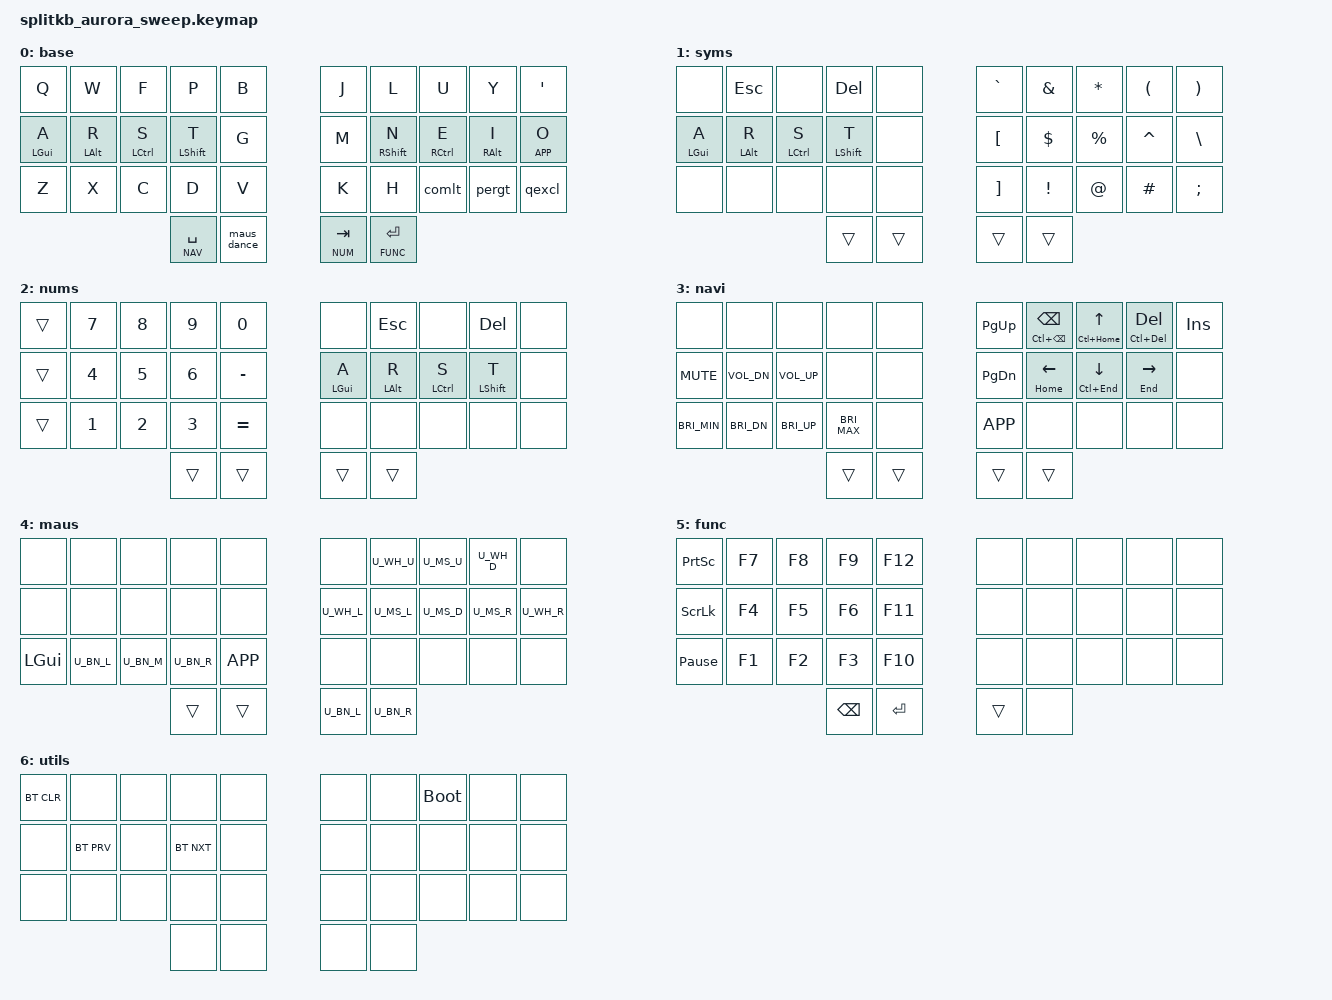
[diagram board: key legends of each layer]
#include <behaviors.dtsi>
#include <dt-bindings/zmk/keys.h>
#include <dt-bindings/zmk/bt.h>

// Initially derived from https://github.com/guruc13/zmk_sweep_colemak_dh
// Which is derived from https://github.com/manna-harbour/miryoku
// Now lots of stuff directly from urob's zmk work

#include "../zmk-nodefree-config/helper.h"
#include "../zmk-nodefree-config/keypos_def/keypos_34keys.h"

#define BASE 0
#define SYM  1    // Hold ---
#define NUM  2    // Hold RH0
#define NAV  3    // Hold LH1
#define MAUS 4    // Hold LH0
#define FUNC 5    // Hold RH1
#define UTIL 6    // Hold RH0 + RH1

// must be sourced after layer-shortcuts and after keypos_34keys.h
#include "combos.dtsi"  // references layer defs we are not using
#include "mouse.dtsi"

&mt {
    flavor = "tap-preferred";
    tapping-term-ms = <220>;
    quick-tap-ms = <220>;              // repeat on tap-into-hold
    hold-trigger-key-positions = <0>;  // tap on interrupt
};

#define NAV_L     &mt HOME     LEFT    // tap: left  | long-tap: beginning of line
#define NAV_R     &mt END      RIGHT   // tap: right | long-tap: end       of line
#define NAV_U     &mt LC(HOME) UP      // tap: up    | long-tap: beginning of document
#define NAV_D     &mt LC(END)  DOWN    // tap: down  | long-tap: end       of document
#define NAV_BSC  &mt LC(BSPC) BSPC    // tap: bspc  | long-tap: delete word backward
#define NAV_DEL   &mt LC(DEL)  DEL     // tap: del   | long-tap: delete word forward


#define KEYS_L LT0 LT1 LT2 LT3 LT4 LM0 LM1 LM2 LM3 LM4 LB0 LB1 LB2 LB3 LB4  // left-hand keys
#define KEYS_R RT0 RT1 RT2 RT3 RT4 RM0 RM1 RM2 RM3 RM4 RB0 RB1 RB2 RB3 RB4  // right-hand keys
#define THUMBS LH1 LH0 RH0 RH1                                      // thumb keys

#define QUICK_TAP_MS 175

ZMK_BEHAVIOR(hml, hold_tap,  // left-hand HRMs
    flavor = "balanced";
    tapping-term-ms = <280>;
    quick-tap-ms = <QUICK_TAP_MS>;
    global-quick-tap-ms = <150>;        // requires PR #1387
    bindings = <&kp>, <&kp>;
    hold-trigger-key-positions = <KEYS_R THUMBS>;
    hold-trigger-on-release;            // requires PR #1423
)


ZMK_BEHAVIOR(hmr, hold_tap,  // right-hand HRMs
    flavor = "balanced";
    tapping-term-ms = <280>;
    quick-tap-ms = <QUICK_TAP_MS>;
    global-quick-tap-ms = <150>;        // requires PR #1387
    bindings = <&kp>, <&kp>;
    hold-trigger-key-positions = <KEYS_L THUMBS>;
    hold-trigger-on-release;            // requires PR #1423
)

// mouse layer that deactivates automatically on all other keys, requires PR #1366
ZMK_BEHAVIOR(smart_maus, tri_state,
    bindings = <&tog MAUS>, <&none>, <&tog MAUS>;
    ignored-key-positions = <RT1 RT2 RT3 RM1 RM2 RM3 RM4 RH0 RH1>;  // mouse keys
    ignored-layers = <MAUS>;
)


// tap:  backspace | double-tap: sticky maus-layer | hold: maus-layer
ZMK_BEHAVIOR(maus_dance, tap_dance,
    tapping-term-ms = <200>;
    bindings = <&kp BSPC>, <&smart_maus>;
)

// tap: qmark | shift + tap: excl
ZMK_BEHAVIOR(qexcl, mod_morph,
    bindings = <&kp QMARK>, <&kp EXCL>;
    mods = <(MOD_LSFT|MOD_RSFT)>;
)

// tap: comma | shift + tap: semi-colon
ZMK_BEHAVIOR(csemi, mod_morph,
    bindings = <&kp COMMA>, <&kp SEMI>;
    mods = <(MOD_LSFT|MOD_RSFT)>;
)

// tap: period | shift + tap: COLON
ZMK_BEHAVIOR(pcolon, mod_morph,
    bindings = <&kp PERIOD>, <&kp COLON>;
    mods = <(MOD_LSFT|MOD_RSFT)>;
)

// tap: period | shift + tap: semi | alt + shift + tap: <
ZMK_BEHAVIOR(comlt, mod_morph,
    bindings = <&kp COMMA>, <&kp LESS_THAN>;
    mods = <(MOD_LALT|MOD_RALT)>;
)

// tap: period | shift + tap: colon | gui + shift + tap: >
ZMK_BEHAVIOR(pergt, mod_morph,
    bindings = <&kp PERIOD>, <&kp GREATER_THAN>;
    mods = <(MOD_LALT|MOD_RALT)>;
)


/ {

  conditional_layers {
    compatible = "zmk,conditional-layers";
    cond_layer_util {
        if-layers = <NUM FUNC>;
        then-layer = <UTIL>;
    };
  };


  keymap {
    compatible = "zmk,keymap";

// 0 BASE LAYER SYM combos
//     4       3       2      1       0             0       1       2      3      4
// ╭───────┬───────┬──────┬───────┬───────╮     ╭───────┬───────┬───────┬──────┬──────╮
// │       │     ESC     TAB      │       │     │       │     LBRC     RBRC    │      │
// │       │       │      │       │       │  T  │       │       │       │      │      │
// ├───────┼──AT───┼─HASH─┼─DLLR──┼─PRCNT─┤     ├─CARET ┼─PLUS──┼─ASTRK─┼─AMPS─┼──────┤
// │       │       │      │       │       │     │       │       │       │      │      │
// │       │    REPEAT   ENTER    │       │  M  │       │     LPAR     RPAR    │      │
// │       │       │      │       │       │     │       │       │       │      │      │
// ├───────┼─GRAVE─┼─BSLH─┼─EQUAL─│ TILDE─┤     ├─UNDER─┼─MINUS─┼─SLASH─┼─PIPE─┼──────┤
// │       │       │      │       │       │     │       │       │       │      │      │
// │       │    COPY    PASTE     │       │  B  │       │     LBKT     RBKT    │      │
// ╰───────┴───────┴──────╮───────┴───────┤     ├───────┴───────╭───────┴──────┴──────╯
//                        │       ┬       │  H  │       ┬       │
//           LEFT         │       │       │     │       │       │    RIGHT
//                        ╰───────┴───────╯     ╰───────┴───────╯
//

// 0 BASE LAYER
// ╭───────┬──────┬───────┬──────┬──────╮     ╭──────┬──────┬───────┬────────┬───────╮
// │       │      │       │      │      │     │      │      │       │        │  DQT  │
// │   Q   │   W  │   F   │   P  │   B  │     │  J   │   L  │   U   │    Y   │  SQT  │
// ├───────┼──────┼───────┼──────┼──────┤     ├──────┼──────┼───────┼────────┼───────┤
// │ LGUI  │ LALT │ LCT L │ LSHT │      │     │      │ LSHT │ LCTL  │  LALT  │ K_APP │
// │   A   │   R  │   S   │   T  │   G  │     │  M   │   N  │   E   │    I   │   O   │
// ├───────┼──────┼───────┼──────┼──────┤     ├──────┼──────┼───────┼────────┼───────┤
// │       │      │       │      │      │     │      │      │   LT  │   GT   │ EXCL  │
// │   Z   │   X  │   C   │   D  │   V  │     │  K   │   H  │ COMMA │ PERIOD │ QMARK │
// ╰───────┴──────┴──╮────┴──────┴──────┤     ├──────┴──────┴─────╭─┴────────┴───────╯
//                   │                  │     │      UTIL(6)      │
//                   │ NAV(3) ┬ MAUS(4) │     │ NUM(2) ┬  FUNC(5) │
//                   │ SPACE  │  BSPC   │     │   TAB  │  ENTER   │
//                   ╰────────┴─────────╯     ╰────────┴──────────╯
//

    base_layer { // layer 0
      label = "base";
      bindings = <
      &kp Q       &kp W       &kp F        &kp P        &kp B     &kp J  &kp L         &kp U        &kp Y        &kp SQT
      &hml LGUI A &hml LALT R &hml LCTRL S &hml LSHFT T &kp G     &kp M  &hmr RSHFT N  &hmr RCTRL E &hmr RALT I &hmr K_APP O
      &kp Z       &kp X       &kp C        &kp D        &kp V     &kp K  &kp H         &comlt    &pergt  &qexcl
                                 &lt NAV SPACE    &maus_dance     &lt NUM TAB  &lt FUNC ENTER
        >;
    };

// 1 SYMS LAYER
// ╭──────┬──────┬──────┬──────┬──────╮    ╭───────┬───────┬───────┬───────┬───────╮
// │      │      │      │      │      │    │ TILDE │       │       │       │       │
// │      │ ESC  │      │ DEL  │      │    │ GRAVE │ AMPS  │ ASTRK │ LPAR  │ RPAR  │
// ├──────┼──────┼──────┼──────┼──────┤    ├───────┼───────┼───────┼───────┼───────┤
// │      │      │      │      │      │    │ LBRC  │       │       │       │ PIPE  │
// │ LGUI │ LALT │ LCTL │ LSHT │      │    │ LBKT  │ DLLR  │ PRCNT │ CARET │ BSLH  │
// ├──────┼──────┼──────┼──────┼──────┤    ├───────┼───────┼───────┼───────┼───────┤
// │      │      │      │      │      │    │ RBRC  │       │       │       │ COLON │
// │      │      │      │      │      │    │ RBKT  │ EXCL  │  AT   │ HASH  │ SEMI  │
// ╰──────┴──────┴────╮─┴──────┴──────┤    ├───────┼───────╭───────┴───────┴───────╯
//                    │    MAUS(4)    │    │               │
//                    │ **** ┬  (NUM) │    │       ┬       │
//                    │ **** │  TRANS │    │ TRANS │ TRANS │
//                    ╰──────┴────────╯    ╰───────┴───────╯
//

    sym_layer { //layer 1
      label = "syms";
      bindings = <
      &none       &kp ESC     &none        &kp DEL      &none      &kp GRAVE &kp AMPS &kp ASTRK &kp LPAR  &kp RPAR
      &hml LGUI A &hml LALT R &hml LCTRL S &hml LSHFT T &none      &kp LBKT  &kp DLLR &kp PRCNT &kp CARET &kp BSLH
      &none       &none       &none        &none        &none      &kp RBKT  &kp EXCL &kp AT    &kp HASH  &kp SEMI
                                           &trans       &trans     &trans    &trans
      >;
    };


// 2 NUMS LAYER
//  ╭───────┬───────┬───────┬───────┬───────╮    ╭───────┬──────┬──────┬──────┬──────╮
//  │       │ AMPS  │ ASTRK │ LPAR  │ RPAR  │    │       │      │      │      │      │
//  │ TRANS │  N7   │   N8  │  N9   │   N0  │    │       │ ESC  │      │ DEL  │      │
//  ├───────┼───────┼───────┼───────┼───────┤    ├───────┼──────┼──────┼──────┼──────┤
//  │       │ DLLR  │ PRCNT │ CARET │ UNDER │    │       │      │      │      │      │
//  │ TRANS │  N4   │   N5  │   N6  │ MINUS │    │ LGUI  │ LALT │ LCTL │ LSHT │      │
//  ├───────┼───────┼───────┼───────┼───────┤    ├───────┼──────┼──────┼──────┼──────┤
//  │       │ EXCL  │   AT  │  HASH │ PLUS  │    │       │      │      │      │      │
//  │ TRANS │  N1   │   N2  │   N3  │ EQUAL │    │       │      │      │      │      │
//  ╰───────┴───────┴───────┼───────├───────┤    ├───────┼───────╭─────┴──────┴──────╯
//                          │               │    │               │
//                          │       ┬       │    │       ┬       │
//                          │ TRANS │ TRANS │    │ TRANS │ TRANS │
//                          ╰───────┴───────╯    ╰───────┴───────╯
//

    num_layer { //layer 2
      label = "nums";
      bindings = <
      &trans &kp N7  &kp N8  &kp N9  &kp N0        &none       &kp ESC     &none        &kp DEL      &none
      &trans &kp N4  &kp N5  &kp N6  &kp MINUS     &hml LGUI A &hml LALT R &hml LCTRL S &hml LSHFT T &none
      &trans &kp N1  &kp N2  &kp N3  &kp EQUAL     &none       &none       &none        &none        &none
                             &trans  &trans         &trans       &trans
      >;
    };


// 3 NAV LAYER
// ╭──────┬──────┬──────┬───────┬───────╮   ╭────────┬────────┬───────┬───────┬────╮
// │      │      │      │       │       │   │ UNDO   │  CUT   │ COPY  │ PASTE │    │
// │      │ HOME │  UP  │ PG_UP │  INS  │   │ LC(Z)  │ LC(X)  │ LC(C) │ LC(V) │    │
// ├──────┼──────┼──────┼───────┼───────┤   ├────────┼────────┼───────┼───────┼────┤
// │      │      │      │       │       │   │        │ K_VOL  │ K_VOL │       │    │
// │ CAPS │ LEFT │ DOWN │ RIGHT │  DEL  │   │ K_MUTE │  _DN   │  _UP  │       │    │
// ├──────┼──────┼──────┼───────┼───────┤   ├────────┼────────┼───────┼───────┼────┤
// │      │      │      │       │       │   │ C_BRI  │ C_BRI  │ C_BRI │ C_BRI │    │
// │ LGUI │ END  │      │ PG_DN │ K_APP │   │  _MIN  │  _DN   │  _UP  │  _MAX │    │
// ╰──────┴──────┴──────╮───────┼───────┤   ├────────┴────────╭───────┴───────┴────╯
//                      │               │   │                 │
//                      │       ┬       │   │        ┬        │
//                      │ TRANS │ TRANS │   │ TRANS  │ TRANS  │
//                      ╰───────┴───────╯   ╰────────┴────────╯
//

    nav_layer { //layer 3
      label = "navi";
      bindings = <
      &none         &none        &none        &none          &none     &kp PG_UP  NAV_BSC NAV_U  NAV_DEL &kp INS
      &kp K_MUTE    &kp K_VOL_DN &kp K_VOL_UP &none          &none     &kp PG_DN  NAV_L   NAV_D  NAV_R   &none
      &kp C_BRI_MIN &kp C_BRI_DN &kp C_BRI_UP &kp C_BRI_MAX  &none     &kp K_APP  &none   &none  &none   &none
                                              &trans         &trans    &trans     &trans
      >;
    };

// 4 MAUS LAYER
// ╭──────┬──────┬──────┬──────┬───────╮  ╭────────┬────────┬────────┬────────┬─────────╮
// │      │      │      │      │       │  │        │ SCROLL │  MOVE  │ SCROLL │         │
// │      │      │      │      │       │  │        │   UP   │   UP   │   IP   │         │
// ├──────┼──────┼──────┼──────┼───────┤  ├────────┼────────┼────────┼────────┼─────────┤
// │      │      │      │      │       │  │ SCROLL │  MOVE  │  MOVE  │  MOVE  │ SCROLL  │
// │ LGUI │ LCLK │ MCLK │ RCLK │ K_APP │  │  LEFT  │  LEFT  │   DN   │   RT   │   RT    │
// ├──────┼───── ┼──────┼──────┼───────┤  ├────────┼────────┼────────┼────────┼─────────┤
// │      │      │      │      │       │  │        │        │        │        │         │
// │      │      │      │      │       │  │        │        │        │        │         │
// ╰──────┴──────┴──────╮──────┼───────┤  ├────────┼────────╭────────┴────────┴─────────╯
//                      │ **** ┬ ****  │  │        ┬        │
//                      │ **** │ ****  │  │  LCLK  │ RCLK   │
//                      ╰──────┴───────╯  ╰────────┴────────╯
//

    maus_layer { // layer 4
      label = "maus";
      bindings = <
      &none     &none   &none   &none   &none        &none   U_WH_U  U_MS_U  U_WH_D  &none
      &none     &none   &none   &none   &none        U_WH_L  U_MS_L  U_MS_D  U_MS_R  U_WH_R
      &kp LGUI  U_BN_L  U_BN_M  U_BN_R  &kp K_APP    &none   &none   &none   &none   &none
                                &trans  &trans       U_BN_L  U_BN_R
      >;
    };


// 5 FUNC LAYER
// ╭───────┬──────┬──────┬──────┬───────╮  ╭────────┬───────┬──────┬──────┬──────╮
// │       │      │      │      │       │  │        │       │      │      │      │
// │ PSCRN │  F7  │  F8  │  F9  │  F10  │  │        │       │      │      │      │
// ├───────┼──────┼──────┼──────┼───────┤  ├────────┼───────┼──────┼──────┼──────┤
// │       │      │      │      │       │  │        │       │      │      │      │
// │ SLCK  │  F4  │  F5  │  F6  │  F11  │  │        │       │      │      │      │
// ├───────┼──────┼──────┼──────┼───────┤  ├────────┼───────┼──────┼──────┼──────┤
// │ PAUSE │      │      │      │       │  │        │       │      │      │      │
// │ BREAK │  F1  │  F2  │  F3  │  F12  │  │        │       │      │      │      │
// ╰───────┴──────┴──────╮──────┴───────┤  ├────────┴───────╭──────┴──────┴──────╯
//                       │              │  │     UTIL(6)    │
//                       │      ┬       │  │ NAV(3) ┬  **** │
//                       │ BSPC │ ENTER │  │ TRANS  │  **** │
//                       ╰──────┴───────╯  ╰────────┴───────╯
//

    func_layer { // layer 5
      label = "func";
      bindings = <
      &kp PSCRN        &kp F7  &kp F8  &kp F9   &kp F12      &none   &none   &none   &none   &none
      &kp SLCK         &kp F4  &kp F5  &kp F6   &kp F11      &none   &none   &none   &none   &none
      &kp PAUSE_BREAK  &kp F1  &kp F2  &kp F3   &kp F10      &none   &none   &none   &none   &none
                                     &kp BSPC &kp ENTER      &trans  &none
      >;
    };


// 6 UTIL LAYER
// ╭──────┬──────┬────┬──────┬──────╮    ╭──────┬──────┬────────┬─────┬─────╮
// │  BT  │      │    │      │      │    │      │      │  boot  │     │     │
// │ _CLR │      │    │      │      │    │      │      │ loader │     │     │
// ├──────┼──────┼────┼──────┼──────┤    ├──────┼──────┼────────┼─────┼─────┤
// │      │  BT  │    │  BT  │      │    │      │      │        │     │     │
// │      │ _PRV │    │ _NXT │      │    │      │      │        │     │     │
// ├──────┼──────┼────┼──────┼──────┤    ├──────┼──────┼────────┼─────┼─────┤
// │      │      │    │      │      │    │      │      │        │     │     │
// │      │      │    │      │      │    │      │      │        │     │     │
// ╰──────┴──────┴────┼──────┼──────┤    ├──────┴──────┼────────┴─────┴─────╯
//                    │             │    │    UTIL(6)  │
//                    │      ┬      │    │ **** ┬ **** │
//                    │      │      │    │ **** │ **** │
//                    ╰──────┴──────╯    ╰──────┴──────╯
//

    util_layer { // layer 6
      label = "utils";
      bindings = <
      &bt BT_CLR &none      &none   &none      &none        &none   &none   &bootloader &none   &none
      &none      &bt BT_PRV &none   &bt BT_NXT &none        &none   &none   &none       &none   &none
      &none      &none      &none   &none      &none        &none   &none   &none       &none   &none
                                    &none      &none        &none   &none
      >;
    };
  };
};
